# STM32L476xx register map
File version: 1.0
Registers are 32-bit, read-write, reset 0x0 unless marked. A register's access mark holds for its fields unless they carry their own. Offsets are from the block's base; [hi:lo] are bit positions; {n}, {i} and the like mark numbered series.

## PWR — Power Control
Base 0x40007000
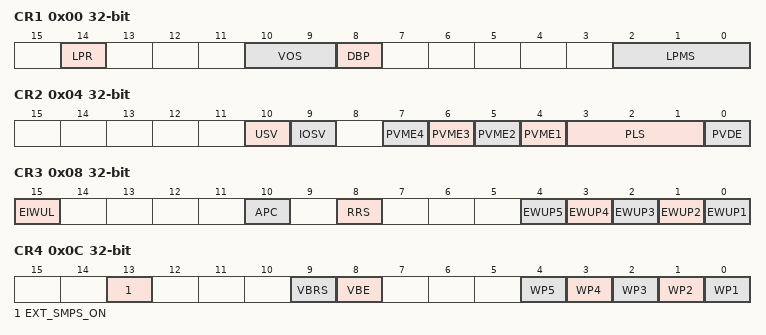
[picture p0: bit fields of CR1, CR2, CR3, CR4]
0x00 CR1 — PWR power control register 1
  [14] LPR — Regulator low-power mode
  [10:9] VOS — VOS[1:0] bits (Regulator voltage scaling output selection)
    1=SCALE1; 2=SCALE2
  [8] DBP — Disable Back-up domain Protection
  [2:0] LPMS — Low-power mode selection field
    0=STOP0; 1=STOP1; 2=STOP2; 3=STANDBY; 4=SHUTDOWN
0x04 CR2 — PWR power control register 2
  [10] USV — VDD USB Supply Valid
  [9] IOSV — VDD IO2 independent I/Os Supply Valid
  [n+3] PVME{n} (n=1..4) — PVM {n} Enable
  [3:1] PLS — PVD level selection
    {v}=PVDLEVEL_{v} (v=0..7)
  [0] PVDE — Power Voltage Detector Enable
0x08 CR3 — PWR power control register 3
  [15] EIWUL — Enable Internal Wake-up line
  [10] APC — Apply pull-up and pull-down configuration
  [8] RRS — SRAM2 Retention in Stand-by mode
    0=NO_SRAM2_RETENTION; 1=FULL_SRAM2_RETENTION
  [n-1] EWUP{n} (n=1..5) — Enable Wake-Up Pin {n}
0x0C CR4 — PWR power control register 4
  [13] EXT_SMPS_ON — Inform the internal regulator on external SMPS switch status
  [9] VBRS — VBAT Battery charging Resistor Selection
    0=CHARG_RESISTOR_5K; 1=CHARGRESISTOR_1_5K
  [8] VBE — VBAT Battery charging Enable
  [n-1] WP{n} (n=1..5) — Wake-Up Pin {n} polarity
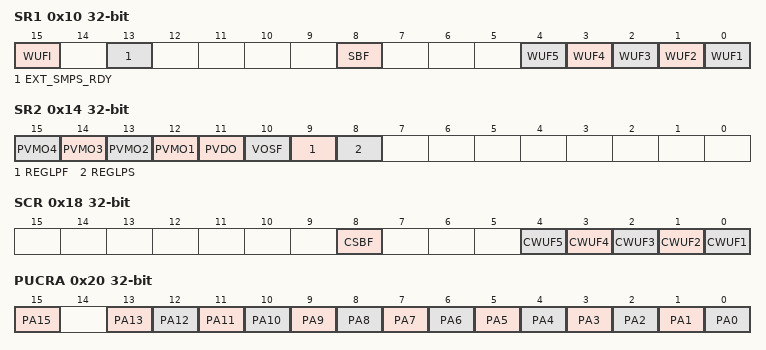
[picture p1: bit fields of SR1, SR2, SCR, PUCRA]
0x10 SR1 — PWR power status register 1
  [15] WUFI — Wake-Up Flag Internal
  [13] EXT_SMPS_RDY — Switching to external SMPS Ready Flag
  [8] SBF — Stand-By Flag
  [n-1] WUF{n} (n=1..5) — Wake-up Flag {n}
0x14 SR2 — PWR power status register 2
  [n+11] PVMO{n} (n=1..4) — Peripheral Voltage Monitoring Output {n}
  [11] PVDO — Power Voltage Detector Output
  [10] VOSF — Voltage Scaling Flag
  [9] REGLPF — Low-power Regulator Flag
  [8] REGLPS — Low-power Regulator Started
0x18 SCR — PWR power status reset register
  [8] CSBF — Clear Stand-By Flag
  [n-1] CWUF{n} (n=1..5) — Clear Wake-up Flag {n}
0x20 PUCRA — Pull_up control register of portA
  [15] PA15 — Port PA15 Pull-Up set
  [n] PA{n} (n=0..13) — Port PA{n} Pull-Up set
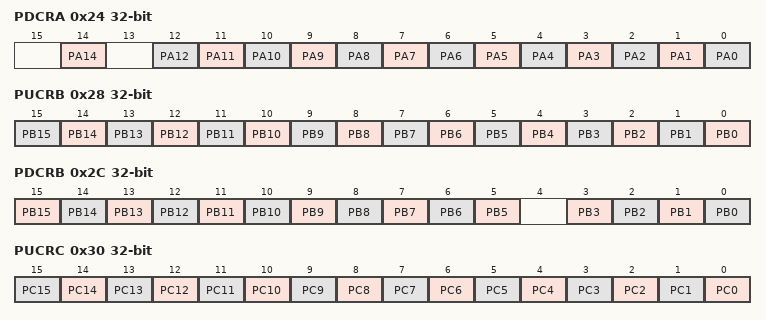
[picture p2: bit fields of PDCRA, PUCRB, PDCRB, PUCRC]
0x24 PDCRA — Pull_Down control register of portA
  [14] PA14 — Port PA14 Pull-Down set
  [n] PA{n} (n=0..12) — Port PA{n} Pull-Down set
0x28 PUCRB — Pull_up control register of portB
  [n] PB{n} (n=0..15) — Port PB{n} Pull-Up set
0x2C PDCRB — Pull_Down control register of portB
  [n] PB{n} (n=5..15) — Port PB{n} Pull-Down set
  [n] PB{n} (n=0..3) — Port PB{n} Pull-Down set
0x30 PUCRC — Pull_up control register of portC
  [n] PC{n} (n=0..15) — Port PC{n} Pull-Up set
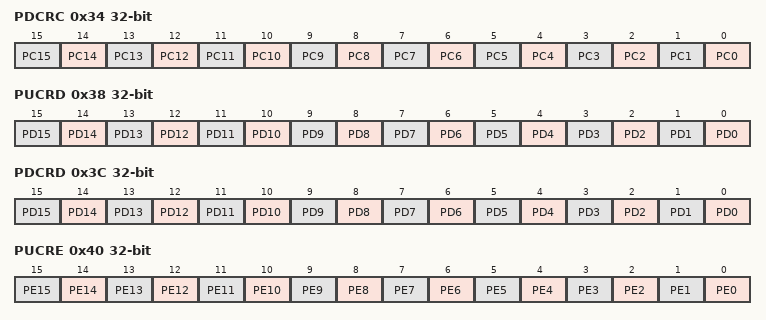
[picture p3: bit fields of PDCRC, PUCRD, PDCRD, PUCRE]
0x34 PDCRC — Pull_Down control register of portC
  [n] PC{n} (n=0..15) — Port PC{n} Pull-Down set
0x38 PUCRD — Pull_up control register of portD
  [n] PD{n} (n=0..15) — Port PD{n} Pull-Up set
0x3C PDCRD — Pull_Down control register of portD
  [n] PD{n} (n=0..15) — Port PD{n} Pull-Down set
0x40 PUCRE — Pull_up control register of portE
  [n] PE{n} (n=0..15) — Port PE{n} Pull-Up set
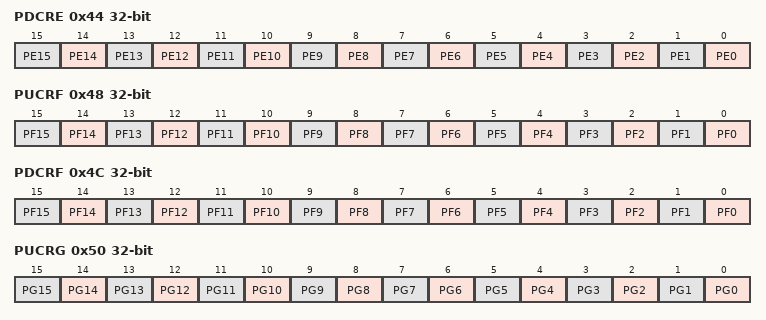
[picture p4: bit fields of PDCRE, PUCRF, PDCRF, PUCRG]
0x44 PDCRE — Pull_Down control register of portE
  [n] PE{n} (n=0..15) — Port PE{n} Pull-Down set
0x48 PUCRF — Pull_up control register of portF
  [n] PF{n} (n=0..15) — Port PF{n} Pull-Up set
0x4C PDCRF — Pull_Down control register of portF
  [n] PF{n} (n=0..15) — Port PF{n} Pull-Down set
0x50 PUCRG — Pull_up control register of portG
  [n] PG{n} (n=0..15) — Port PG{n} Pull-Up set
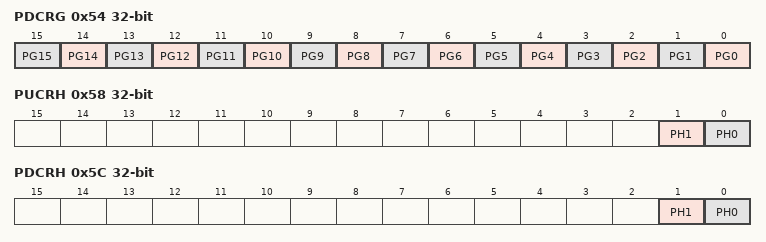
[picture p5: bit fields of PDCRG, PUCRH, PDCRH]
0x54 PDCRG — Pull_Down control register of portG
  [n] PG{n} (n=0..15) — Port PG{n} Pull-Down set
0x58 PUCRH — Pull_up control register of portH
  [1] PH1 — Port PH1 Pull-Up set
  [0] PH0 — Port PH0 Pull-Up set
0x5C PDCRH — Pull_Down control register of portH
  [1] PH1 — Port PH1 Pull-Down set
  [0] PH0 — Port PH0 Pull-Down set

## OPAMP — Operational Amplifier (OPAMP)
Base 0x40007800
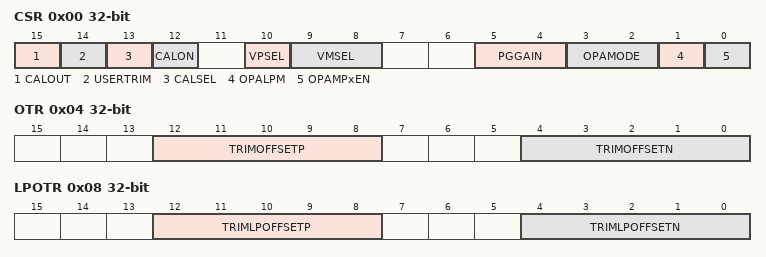
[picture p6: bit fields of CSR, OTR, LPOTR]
0x00 CSR — OPAMP control/status register
  [15] CALOUT — Operational amplifier1 calibration output
  [14] USERTRIM — User trimming enable
    0=FACTORY (OPAMP trimming factors set to factory values); 1=USER (OPAMP trimming factors set to user values)
  [13] CALSEL — Calibration selection
  [12] CALON — Calibration mode enable
    0=FUNCTIONAL (OPAMP functional mode); 1=CALIBRATION (OPAMP calibration mode)
  [10] VPSEL — Non inverted input selection
    0=NONINVERT_IO0 (OPAMP non inverting input connected to GPIO pin (pin PA0 for OPAMP1, pin PA6 for OPAMP2)); 1=NONINV_DAC1_CH1 (OPAMP non inverting input connected to DAC1 channel1 output)
  [9:8] VMSEL — Inverting input selection
    0=IO0 (OPAMP inverting input connected to GPIO pin (valid also in PGA mode for filtering). Note: OPAMP inverting input is used with OPAMP in mode standalone or PGA with external capacitors for filtering circuit. Otherwise (OPAMP in mode follower), OPAMP inverting input is not used (not connected to GPIO pin).); 1=IO1 (OPAMP inverting input (low leakage input) connected to GPIO pin (available only on package BGA132). Note: OPAMP inverting input is used with OPAMP in mode standalone or PGA with external capacitors for filtering circuit. Otherwise (OPAMP in mode follower), OPAMP inverting input is not used (not connected to GPIO pin).); 2=CONNECT_NO (OPAMP inverting input not externally connected (intended for OPAMP in mode follower or PGA without external capacitors for filtering))
  [5:4] PGGAIN — Operational amplifier Programmable amplifier gain value
    0=GAIN_2 (OPAMP PGA gain 2); 1=GAIN_4 (OPAMP PGA gain 4); 2=GAIN_8 (OPAMP PGA gain 8); 3=GAIN_16 (OPAMP PGA gain 16)
  [3:2] OPAMODE — Operational amplifier PGA mode
    0=STANDALONE (OPAMP functional mode, OPAMP operation in standalone); 3=FOLLOWER (OPAMP functional mode, OPAMP operation in follower); 2=PGA (OPAMP functional mode, OPAMP operation in PGA)
  [1] OPALPM — Operational amplifier Low Power Mode
  [0] OPAMPxEN — OPAMP enable
0x04 OTR — OPAMP
  [12:8] TRIMOFFSETP — Trim for PMOS differential pairs
  [4:0] TRIMOFFSETN — Trim for NMOS differential pairs
0x08 LPOTR — OPAMP
  [12:8] TRIMLPOFFSETP — Trim for PMOS differential pairs
  [4:0] TRIMLPOFFSETN — Trim for NMOS differential pairs
